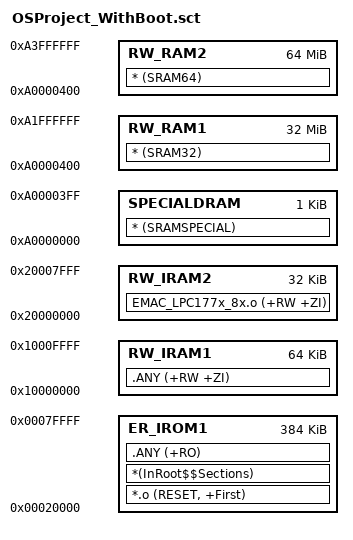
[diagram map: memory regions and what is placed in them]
; *************************************************************
; *** Scatter-Loading Description File generated by uVision ***
; *************************************************************

LR_IROM1 0x00020000 0x00060000  {    ; load region size_region
  ER_IROM1 0x00020000 0x00060000  {  ; load address = execution address
   *.o (RESET, +First)
   *(InRoot$$Sections)
   .ANY (+RO)
  }
  SPECIALDRAM   0XA0000000  0x00000400
 {
   * (SRAMSPECIAL)
 }
   RW_RAM1 0xA0000400 0x01FFFC00  {  ; RW data
    * (SRAM32)
   } 
   RW_RAM2 0xA0000400 0x03FFFC00  {  ; RW data
    * (SRAM64)
  }
  RW_IRAM1 0x10000000 0x00010000  {
   .ANY (+RW +ZI)
  }
  ;RW_IRAM2 0x20000000 0x00004000  {
  ;     .ANY (+RW +ZI)
  ;}
  
  ;  RW_IRAM3 0x20004000 0x00004000  {
 ;	   EMAC_LPC177x_8x.o (+RW +ZI)
  ;}
  RW_IRAM2 0x20000000 0x00008000  {
 	   EMAC_LPC177x_8x.o (+RW +ZI)
  }
}

